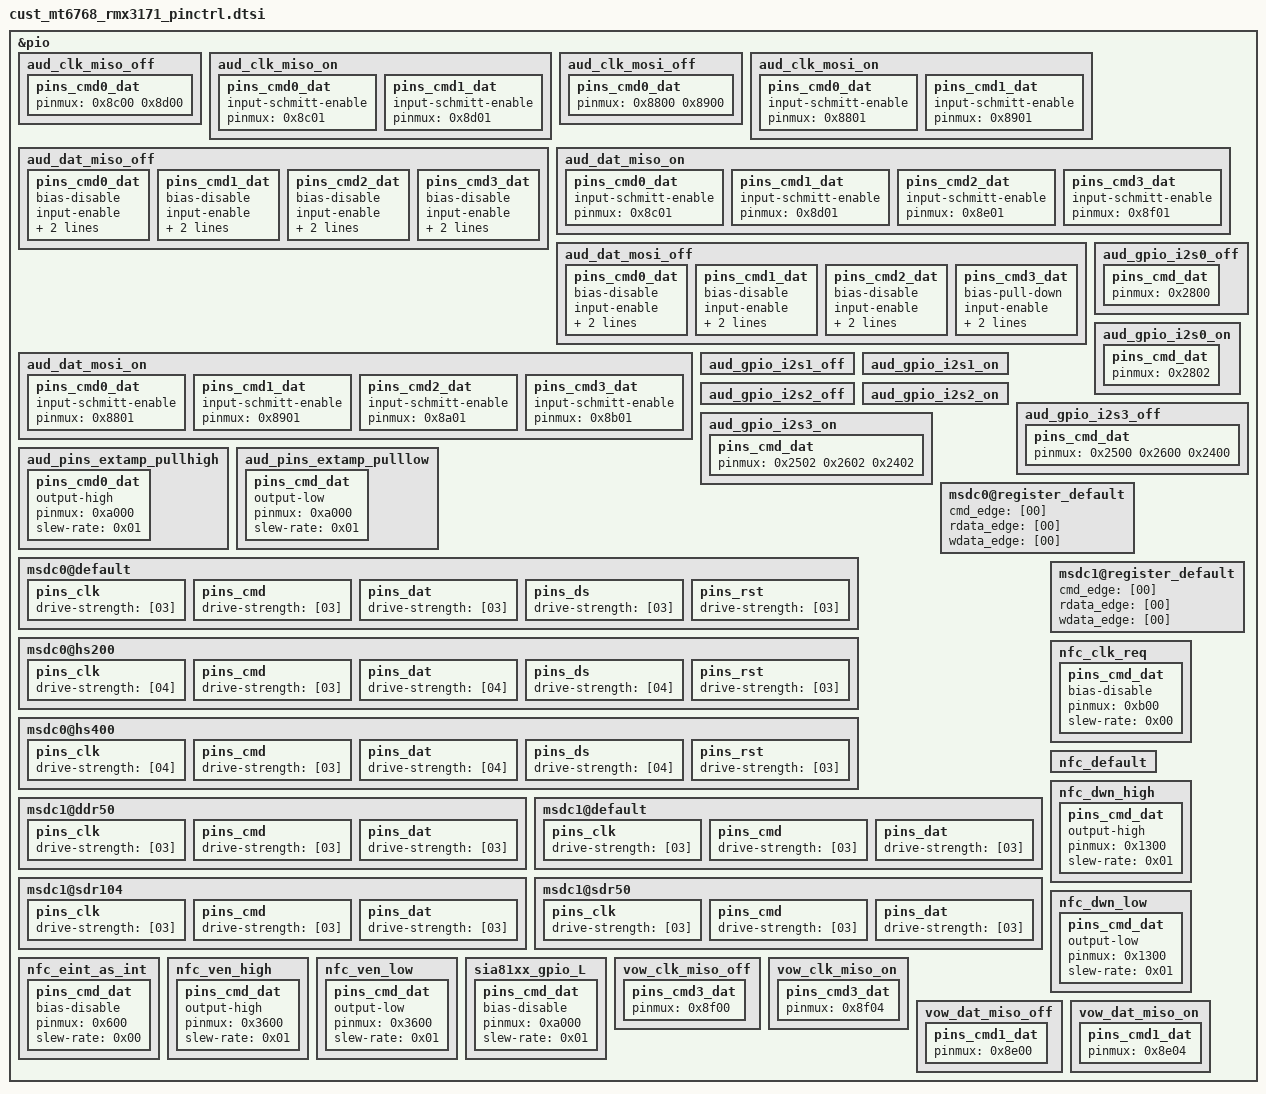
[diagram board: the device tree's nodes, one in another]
// SPDX-License-Identifier: GPL-2.0+
/*
 * AETHER RMX3171 — pinctrl extracted from stock A11 boot dtb.
 *
 * Source: realme_rmx3171_dump-RMX3171_11.A.13_0130/bootdts/01_dtbdump_MT6768.dts
 *         (decompiled stock factory boot image)
 *
 * Pinmux values are raw 32-bit MTK encodings: function | flags. Stock
 * Realme A11 build of RMX3171 uses these for ALL gpio/audio/charger
 * pin groups. Reference by phandle from device nodes via
 *   pinctrl-N = <&group_name>;
 *
 * For 6.6-style symbolic macros see
 *   include/dt-bindings/pinctrl/mt6768-pinfunc.h
 * but those are NOT applied here to preserve byte-equivalence with stock.
 *
 * Generated by aether-rmx3171/build/extract_rmx3171_pinctrl.sh
 */

&pio {

		aud_clk_miso_off {

			pins_cmd0_dat {
				pinmux = <0x8c00 0x8d00>;
			};
		};

		aud_clk_miso_on {

			pins_cmd0_dat {
				input-schmitt-enable;
				pinmux = <0x8c01>;
			};

			pins_cmd1_dat {
				input-schmitt-enable;
				pinmux = <0x8d01>;
			};
		};

		aud_clk_mosi_off {

			pins_cmd0_dat {
				pinmux = <0x8800 0x8900>;
			};
		};

		aud_clk_mosi_on {

			pins_cmd0_dat {
				input-schmitt-enable;
				pinmux = <0x8801>;
			};

			pins_cmd1_dat {
				input-schmitt-enable;
				pinmux = <0x8901>;
			};
		};

		aud_dat_miso_off {

			pins_cmd0_dat {
				bias-disable;
				input-enable;
				pinmux = <0x8c00>;
				slew-rate = <0x00>;
			};

			pins_cmd1_dat {
				bias-disable;
				input-enable;
				pinmux = <0x8d00>;
				slew-rate = <0x00>;
			};

			pins_cmd2_dat {
				bias-disable;
				input-enable;
				pinmux = <0x8e00>;
				slew-rate = <0x00>;
			};

			pins_cmd3_dat {
				bias-disable;
				input-enable;
				pinmux = <0x8f00>;
				slew-rate = <0x00>;
			};
		};

		aud_dat_miso_on {

			pins_cmd0_dat {
				input-schmitt-enable;
				pinmux = <0x8c01>;
			};

			pins_cmd1_dat {
				input-schmitt-enable;
				pinmux = <0x8d01>;
			};

			pins_cmd2_dat {
				input-schmitt-enable;
				pinmux = <0x8e01>;
			};

			pins_cmd3_dat {
				input-schmitt-enable;
				pinmux = <0x8f01>;
			};
		};

		aud_dat_mosi_off {

			pins_cmd0_dat {
				bias-disable;
				input-enable;
				pinmux = <0x8800>;
				slew-rate = <0x00>;
			};

			pins_cmd1_dat {
				bias-disable;
				input-enable;
				pinmux = <0x8900>;
				slew-rate = <0x00>;
			};

			pins_cmd2_dat {
				bias-disable;
				input-enable;
				pinmux = <0x8a00>;
				slew-rate = <0x00>;
			};

			pins_cmd3_dat {
				bias-pull-down;
				input-enable;
				pinmux = <0x8b00>;
				slew-rate = <0x00>;
			};
		};

		aud_dat_mosi_on {

			pins_cmd0_dat {
				input-schmitt-enable;
				pinmux = <0x8801>;
			};

			pins_cmd1_dat {
				input-schmitt-enable;
				pinmux = <0x8901>;
			};

			pins_cmd2_dat {
				input-schmitt-enable;
				pinmux = <0x8a01>;
			};

			pins_cmd3_dat {
				input-schmitt-enable;
				pinmux = <0x8b01>;
			};
		};

		aud_gpio_i2s0_off {

			pins_cmd_dat {
				pinmux = <0x2800>;
			};
		};

		aud_gpio_i2s0_on {

			pins_cmd_dat {
				pinmux = <0x2802>;
			};
		};

		aud_gpio_i2s1_off {
		};

		aud_gpio_i2s1_on {
		};

		aud_gpio_i2s2_off {
		};

		aud_gpio_i2s2_on {
		};

		aud_gpio_i2s3_off {

			pins_cmd_dat {
				pinmux = <0x2500 0x2600 0x2400>;
			};
		};

		aud_gpio_i2s3_on {

			pins_cmd_dat {
				pinmux = <0x2502 0x2602 0x2402>;
			};
		};

		aud_pins_extamp_pullhigh {

			pins_cmd0_dat {
				output-high;
				pinmux = <0xa000>;
				slew-rate = <0x01>;
			};
		};

		aud_pins_extamp_pulllow {

			pins_cmd_dat {
				output-low;
				pinmux = <0xa000>;
				slew-rate = <0x01>;
			};
		};

		msdc0@default {

			pins_clk {
				drive-strength = [03];
			};

			pins_cmd {
				drive-strength = [03];
			};

			pins_dat {
				drive-strength = [03];
			};

			pins_ds {
				drive-strength = [03];
			};

			pins_rst {
				drive-strength = [03];
			};
		};

		msdc0@hs200 {

			pins_clk {
				drive-strength = [04];
			};

			pins_cmd {
				drive-strength = [03];
			};

			pins_dat {
				drive-strength = [04];
			};

			pins_ds {
				drive-strength = [04];
			};

			pins_rst {
				drive-strength = [03];
			};
		};

		msdc0@hs400 {

			pins_clk {
				drive-strength = [04];
			};

			pins_cmd {
				drive-strength = [03];
			};

			pins_dat {
				drive-strength = [04];
			};

			pins_ds {
				drive-strength = [04];
			};

			pins_rst {
				drive-strength = [03];
			};
		};

		msdc0@register_default {
			cmd_edge = [00];
			rdata_edge = [00];
			wdata_edge = [00];
		};

		msdc1@ddr50 {

			pins_clk {
				drive-strength = [03];
			};

			pins_cmd {
				drive-strength = [03];
			};

			pins_dat {
				drive-strength = [03];
			};
		};

		msdc1@default {

			pins_clk {
				drive-strength = [03];
			};

			pins_cmd {
				drive-strength = [03];
			};

			pins_dat {
				drive-strength = [03];
			};
		};

		msdc1@register_default {
			cmd_edge = [00];
			rdata_edge = [00];
			wdata_edge = [00];
		};

		msdc1@sdr104 {

			pins_clk {
				drive-strength = [03];
			};

			pins_cmd {
				drive-strength = [03];
			};

			pins_dat {
				drive-strength = [03];
			};
		};

		msdc1@sdr50 {

			pins_clk {
				drive-strength = [03];
			};

			pins_cmd {
				drive-strength = [03];
			};

			pins_dat {
				drive-strength = [03];
			};
		};

		nfc_clk_req {

			pins_cmd_dat {
				bias-disable;
				pinmux = <0xb00>;
				slew-rate = <0x00>;
			};
		};

		nfc_default {
		};

		nfc_dwn_high {

			pins_cmd_dat {
				output-high;
				pinmux = <0x1300>;
				slew-rate = <0x01>;
			};
		};

		nfc_dwn_low {

			pins_cmd_dat {
				output-low;
				pinmux = <0x1300>;
				slew-rate = <0x01>;
			};
		};

		nfc_eint_as_int {

			pins_cmd_dat {
				bias-disable;
				pinmux = <0x600>;
				slew-rate = <0x00>;
			};
		};

		nfc_ven_high {

			pins_cmd_dat {
				output-high;
				pinmux = <0x3600>;
				slew-rate = <0x01>;
			};
		};

		nfc_ven_low {

			pins_cmd_dat {
				output-low;
				pinmux = <0x3600>;
				slew-rate = <0x01>;
			};
		};

		sia81xx_gpio_L {

			pins_cmd_dat {
				bias-disable;
				pinmux = <0xa000>;
				slew-rate = <0x01>;
			};
		};

		vow_clk_miso_off {

			pins_cmd3_dat {
				pinmux = <0x8f00>;
			};
		};

		vow_clk_miso_on {

			pins_cmd3_dat {
				pinmux = <0x8f04>;
			};
		};

		vow_dat_miso_off {

			pins_cmd1_dat {
				pinmux = <0x8e00>;
			};
		};

		vow_dat_miso_on {

			pins_cmd1_dat {
				pinmux = <0x8e04>;
			};
		};
	};
